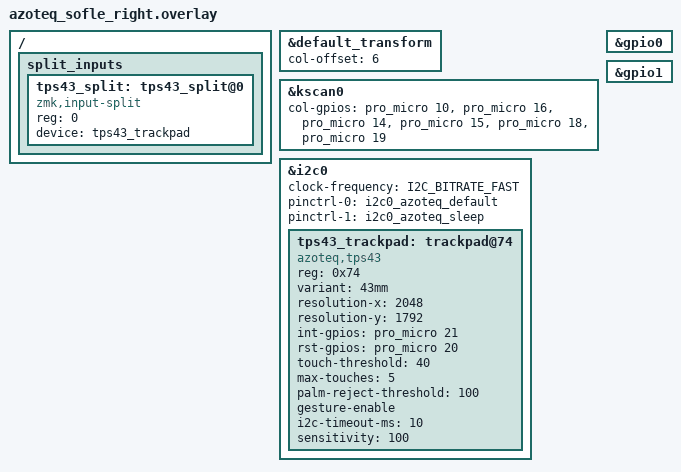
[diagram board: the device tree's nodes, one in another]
#include <zephyr/dt-bindings/i2c/i2c.h>
#include <dt-bindings/pinctrl/nrf-pinctrl.h>
#include <dt-bindings/gpio/gpio.h>

#include "azoteq_sofle.dtsi"
#include "azoteq_sofle-pinctrl.dtsi"

&default_transform {
    col-offset = <6>;
};

&kscan0 {
    col-gpios
        = <&pro_micro 10 GPIO_ACTIVE_HIGH>
        , <&pro_micro 16 GPIO_ACTIVE_HIGH>
        , <&pro_micro 14 GPIO_ACTIVE_HIGH>
        , <&pro_micro 15 GPIO_ACTIVE_HIGH>
        , <&pro_micro 18 GPIO_ACTIVE_HIGH>
        , <&pro_micro 19 GPIO_ACTIVE_HIGH>
        ;
};



// Enable GPIO controllers
&gpio0 {
    status = "okay";
};

&gpio1 {
    status = "okay";
};

/* pro_micro_i2c i2c1*/
&i2c0 {
    status = "okay";
    clock-frequency = <I2C_BITRATE_FAST>;
    pinctrl-0 = <&i2c0_azoteq_default>;
    pinctrl-1 = <&i2c0_azoteq_sleep>;
    pinctrl-names = "default", "sleep";

    tps43_trackpad: trackpad@74 {
        compatible = "azoteq,tps43";
        reg = <0x74>;
        status = "okay";
        
        /* Device variant and resolution */
        variant = "43mm";                    /* 43mm x 40mm trackpad */
        resolution-x = <2048>;               /* X-axis resolution */
        resolution-y = <1792>;               /* Y-axis resolution */
        
        /* GPIO connections (adjust pin numbers for your board) */
        int-gpios = <&pro_micro 21 GPIO_ACTIVE_HIGH>;  /* interrupt pin */
        rst-gpios = <&pro_micro 20 GPIO_ACTIVE_HIGH>;  /* Reset pin */
        
        /* Touch detection settings */
        touch-threshold = <40>;              /* Touch sensitivity (lower = more sensitive) */
        max-touches = <5>;                   /* Maximum simultaneous touches */
        palm-reject-threshold = <100>;       /* Ignore touches larger than this */
        
        /* Feature enablement */
        gesture-enable;                      /* Enable gesture recognition */
        
        /* Communication settings */
        i2c-timeout-ms = <10>;               /* I2C timeout in milliseconds */
        
        /* Input driver settings */
        sensitivity = <100>;                  /* Sensitivity multiplier (percentage) */
    };
};

/ {
    split_inputs {
        #address-cells = <1>;
        #size-cells = <0>;

        tps43_split: tps43_split@0 {
            compatible = "zmk,input-split";
            reg = <0>;
            device = <&tps43_trackpad>;
        };
    };
};
